VERSION ""

NS_ :

BS_:

BU_:

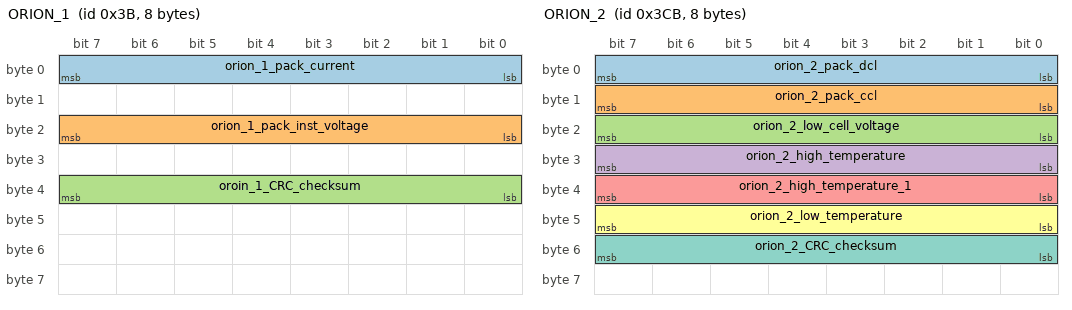
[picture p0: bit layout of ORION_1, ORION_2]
BO_ 59 ORION_1: 8 Vector__XXX
 SG_ orion_1_pack_current : 0|8@1+ (1,0) [0|0] "" Vector__XXX
 SG_ orion_1_pack_inst_voltage : 16|8@1+ (0.1,0) [0|0] "" Vector__XXX
 SG_ oroin_1_CRC_checksum : 32|8@1+ (1,64) [0|0] "" Vector__XXX

BO_ 971 ORION_2: 8 Vector__XXX
 SG_ orion_2_pack_dcl : 0|8@1+ (1,0) [0|0] "" Vector__XXX
 SG_ orion_2_pack_ccl : 8|8@1+ (1,0) [0|0] "" Vector__XXX
 SG_ orion_2_low_cell_voltage : 16|8@1+ (1,0) [0|0] "" Vector__XXX
 SG_ orion_2_high_temperature : 24|8@1+ (1,0) [0|0] "" Vector__XXX
 SG_ orion_2_high_temperature_1 : 32|8@1+ (1,0) [0|0] "" Vector__XXX
 SG_ orion_2_low_temperature : 40|8@1+ (1,0) [0|0] "" Vector__XXX
 SG_ orion_2_CRC_checksum : 48|8@1+ (981,0) [0|0] "" Vector__XXX

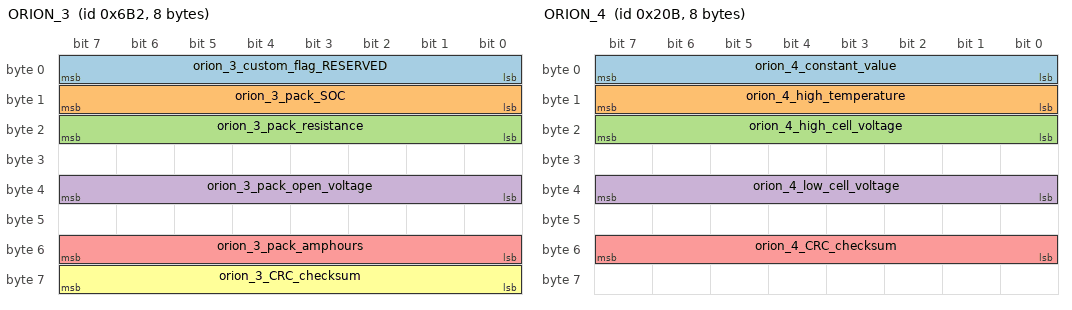
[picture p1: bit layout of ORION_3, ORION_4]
BO_ 1714 ORION_3: 8 Vector__XXX
 SG_ orion_3_custom_flag_RESERVED : 0|8@1+ (1,0) [0|0] "" Vector__XXX
 SG_ orion_3_pack_SOC : 8|8@1+ (0.2,0) [0|0] "" Vector__XXX
 SG_ orion_3_pack_resistance : 16|8@1+ (1,0) [0|0] "" Vector__XXX
 SG_ orion_3_pack_open_voltage : 32|8@1+ (10,0) [0|0] "" Vector__XXX
 SG_ orion_3_pack_amphours : 48|8@1+ (1,0) [0|0] "" Vector__XXX
 SG_ orion_3_CRC_checksum : 56|8@1+ (1,0) [0|0] "" Vector__XXX

BO_ 523 ORION_4: 8 Vector__XXX
 SG_ orion_4_constant_value : 0|8@1+ (1,0) [0|0] "" Vector__XXX
 SG_ orion_4_high_temperature : 8|8@1+ (1,0) [0|0] "" Vector__XXX
 SG_ orion_4_high_cell_voltage : 16|8@1+ (1,0) [0|0] "" Vector__XXX
 SG_ orion_4_low_cell_voltage : 32|8@1+ (1,0) [0|0] "" Vector__XXX
 SG_ orion_4_CRC_checksum : 48|8@1+ (1,0) [0|0] "" Vector__XXX

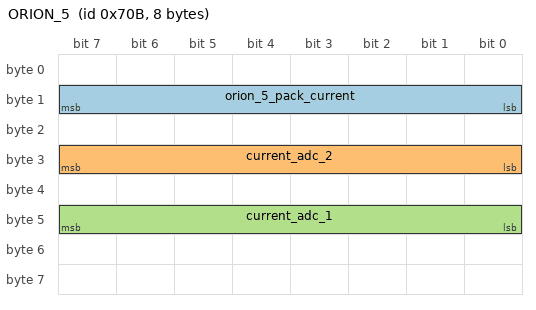
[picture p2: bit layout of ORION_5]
BO_ 1803 ORION_5: 8 Vector__XXX
 SG_ orion_5_pack_current : 8|8@1+ (1,0) [0|0] "" Vector__XXX
 SG_ current_adc_2 : 24|8@1+ (1,0) [0|0] "" Vector__XXX
 SG_ current_adc_1 : 40|8@1+ (1,0) [0|0] "" Vector__XXX

BO_ 105 ORION_DEBUG: 8 Vector__XXX
 SG_ orion_lowest_cell_id : 0|8@1+ (1,0) [0|0] "" Vector__XXX
 SG_ orion_lowest_voltage : 8|8@1+ (1,0) [0|0] "" Vector__XXX
